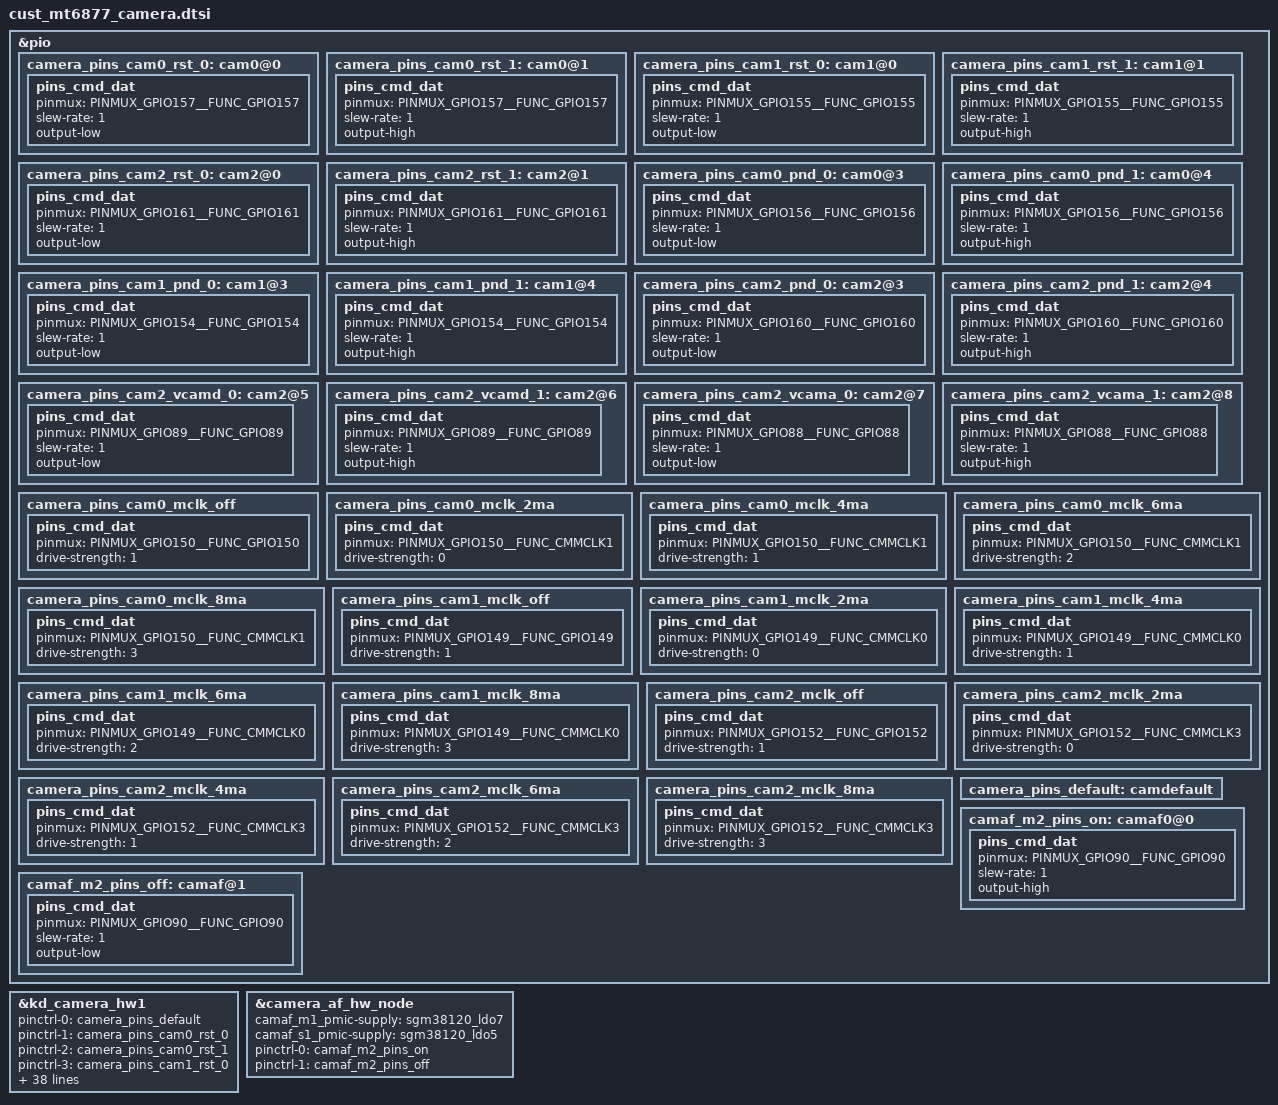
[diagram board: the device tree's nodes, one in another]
// SPDX-License-Identifier: GPL-2.0
/*
 * Copyright (c) 2021 MediaTek Inc.
 */

/* CAMERA GPIO standardization */
&pio {
	camera_pins_cam0_rst_0: cam0@0 {
		pins_cmd_dat {
			pinmux = <PINMUX_GPIO157__FUNC_GPIO157>;
			slew-rate = <1>;
			output-low;
		};
	};
	camera_pins_cam0_rst_1: cam0@1 {
		pins_cmd_dat {
			pinmux = <PINMUX_GPIO157__FUNC_GPIO157>;
			slew-rate = <1>;
			output-high;
		};
	};

	camera_pins_cam1_rst_0: cam1@0 {
		pins_cmd_dat {
			pinmux = <PINMUX_GPIO155__FUNC_GPIO155>;
			slew-rate = <1>;
			output-low;
		};
	};
	camera_pins_cam1_rst_1: cam1@1 {
		pins_cmd_dat {
			pinmux = <PINMUX_GPIO155__FUNC_GPIO155>;
			slew-rate = <1>;
			output-high;
		};
	};

	camera_pins_cam2_rst_0: cam2@0 {
		pins_cmd_dat {
			pinmux = <PINMUX_GPIO161__FUNC_GPIO161>;
			slew-rate = <1>;
			output-low;
		};
	};
	camera_pins_cam2_rst_1: cam2@1 {
		pins_cmd_dat {
			pinmux = <PINMUX_GPIO161__FUNC_GPIO161>;
			slew-rate = <1>;
			output-high;
		};
	};
	
	camera_pins_cam0_pnd_0: cam0@3 {
		pins_cmd_dat {
			pinmux = <PINMUX_GPIO156__FUNC_GPIO156>;
			slew-rate = <1>;
			output-low;
		};
	};
	camera_pins_cam0_pnd_1: cam0@4 {
		pins_cmd_dat {
			pinmux = <PINMUX_GPIO156__FUNC_GPIO156>;
			slew-rate = <1>;
			output-high;
		};
	};

	camera_pins_cam1_pnd_0: cam1@3 {
		pins_cmd_dat {
			pinmux = <PINMUX_GPIO154__FUNC_GPIO154>;
			slew-rate = <1>;
			output-low;
		};
	};
	camera_pins_cam1_pnd_1: cam1@4 {
		pins_cmd_dat {
			pinmux = <PINMUX_GPIO154__FUNC_GPIO154>;
			slew-rate = <1>;
			output-high;
		};
	};

	camera_pins_cam2_pnd_0: cam2@3 {
		pins_cmd_dat {
			pinmux = <PINMUX_GPIO160__FUNC_GPIO160>;
			slew-rate = <1>;
			output-low;
		};
	};
	camera_pins_cam2_pnd_1: cam2@4 {
		pins_cmd_dat {
			pinmux = <PINMUX_GPIO160__FUNC_GPIO160>;
			slew-rate = <1>;
			output-high;
		};
	};

	camera_pins_cam2_vcamd_0: cam2@5 {
		pins_cmd_dat {
			pinmux = <PINMUX_GPIO89__FUNC_GPIO89>;
			slew-rate = <1>;
			output-low;
		};
	};
	
	camera_pins_cam2_vcamd_1: cam2@6 {
		pins_cmd_dat {
			pinmux = <PINMUX_GPIO89__FUNC_GPIO89>;
			slew-rate = <1>;
			output-high;
		};
	};
	
	camera_pins_cam2_vcama_0: cam2@7 {
		pins_cmd_dat {
			pinmux = <PINMUX_GPIO88__FUNC_GPIO88>;
			slew-rate = <1>;
			output-low;
		};
	};
	
	camera_pins_cam2_vcama_1: cam2@8 {
		pins_cmd_dat {
			pinmux = <PINMUX_GPIO88__FUNC_GPIO88>;
			slew-rate = <1>;
			output-high;
		};
	};

	camera_pins_cam0_mclk_off: camera_pins_cam0_mclk_off {
		pins_cmd_dat {
			pinmux = <PINMUX_GPIO150__FUNC_GPIO150>;
			drive-strength = <1>;
		};
	};
	camera_pins_cam0_mclk_2ma: camera_pins_cam0_mclk_2ma {
		pins_cmd_dat {
			pinmux = <PINMUX_GPIO150__FUNC_CMMCLK1>;
			drive-strength = <0>;
		};
	};
	camera_pins_cam0_mclk_4ma: camera_pins_cam0_mclk_4ma {
		pins_cmd_dat {
			pinmux = <PINMUX_GPIO150__FUNC_CMMCLK1>;
			drive-strength = <1>;
		};
	};
	camera_pins_cam0_mclk_6ma: camera_pins_cam0_mclk_6ma {
		pins_cmd_dat {
			pinmux = <PINMUX_GPIO150__FUNC_CMMCLK1>;
			drive-strength = <2>;
		};
	};
	camera_pins_cam0_mclk_8ma: camera_pins_cam0_mclk_8ma {
		pins_cmd_dat {
			pinmux = <PINMUX_GPIO150__FUNC_CMMCLK1>;
			drive-strength = <3>;
		};
	};
	camera_pins_cam1_mclk_off: camera_pins_cam1_mclk_off {
		pins_cmd_dat {
			pinmux = <PINMUX_GPIO149__FUNC_GPIO149>;
			drive-strength = <1>;
		};
	};
	camera_pins_cam1_mclk_2ma: camera_pins_cam1_mclk_2ma {
		pins_cmd_dat {
			pinmux = <PINMUX_GPIO149__FUNC_CMMCLK0>;
			drive-strength = <0>;
		};
	};
	camera_pins_cam1_mclk_4ma: camera_pins_cam1_mclk_4ma {
		pins_cmd_dat {
			pinmux = <PINMUX_GPIO149__FUNC_CMMCLK0>;
			drive-strength = <1>;
		};
	};
	camera_pins_cam1_mclk_6ma: camera_pins_cam1_mclk_6ma {
		pins_cmd_dat {
			pinmux = <PINMUX_GPIO149__FUNC_CMMCLK0>;
			drive-strength = <2>;
		};
	};
	camera_pins_cam1_mclk_8ma: camera_pins_cam1_mclk_8ma {
		pins_cmd_dat {
			pinmux = <PINMUX_GPIO149__FUNC_CMMCLK0>;
			drive-strength = <3>;
		};
	};
	camera_pins_cam2_mclk_off: camera_pins_cam2_mclk_off {
		pins_cmd_dat {
			pinmux = <PINMUX_GPIO152__FUNC_GPIO152>;
			drive-strength = <1>;
		};
	};
	camera_pins_cam2_mclk_2ma: camera_pins_cam2_mclk_2ma {
		pins_cmd_dat {
			pinmux = <PINMUX_GPIO152__FUNC_CMMCLK3>;
			drive-strength = <0>;
		};
	};
	camera_pins_cam2_mclk_4ma: camera_pins_cam2_mclk_4ma {
		pins_cmd_dat {
			pinmux = <PINMUX_GPIO152__FUNC_CMMCLK3>;
			drive-strength = <1>;
		};
	};
	camera_pins_cam2_mclk_6ma: camera_pins_cam2_mclk_6ma {
		pins_cmd_dat {
			pinmux = <PINMUX_GPIO152__FUNC_CMMCLK3>;
			drive-strength = <2>;
		};
	};
	camera_pins_cam2_mclk_8ma: camera_pins_cam2_mclk_8ma {
		pins_cmd_dat {
			pinmux = <PINMUX_GPIO152__FUNC_CMMCLK3>;
			drive-strength = <3>;
		};
	};
	camera_pins_default: camdefault {
	};
};

&kd_camera_hw1 {
	pinctrl-names = "default",
			"cam0_rst0", "cam0_rst1",
			"cam1_rst0", "cam1_rst1",
			"cam2_rst0", "cam2_rst1",
			"cam2_ldo_vcamd_0", "cam2_ldo_vcamd_1",
			"cam2_ldo_vcama_0", "cam2_ldo_vcama_1",
			"cam0_mclk_off",
			"cam0_mclk_2mA", "cam0_mclk_4mA",
			"cam0_mclk_6mA", "cam0_mclk_8mA",
			"cam1_mclk_off",
			"cam1_mclk_2mA", "cam1_mclk_4mA",
			"cam1_mclk_6mA", "cam1_mclk_8mA",
			"cam2_mclk_off",
			"cam2_mclk_2mA", "cam2_mclk_4mA",
			"cam2_mclk_6mA", "cam2_mclk_8mA",
			"cam0_pnd0", "cam0_pnd1",
			"cam1_pnd0", "cam1_pnd1",
			"cam2_pnd0", "cam2_pnd1";

	pinctrl-0 = <&camera_pins_default>;
	pinctrl-1 = <&camera_pins_cam0_rst_0>;
	pinctrl-2 = <&camera_pins_cam0_rst_1>;
	pinctrl-3 = <&camera_pins_cam1_rst_0>;
	pinctrl-4 = <&camera_pins_cam1_rst_1>;
	pinctrl-5 = <&camera_pins_cam2_rst_0>;
	pinctrl-6 = <&camera_pins_cam2_rst_1>;
	pinctrl-7 = <&camera_pins_cam2_vcamd_0>;
	pinctrl-8 = <&camera_pins_cam2_vcamd_1>;
	pinctrl-9 = <&camera_pins_cam2_vcama_0>;
	pinctrl-10 = <&camera_pins_cam2_vcama_1>;
	pinctrl-11 = <&camera_pins_cam0_mclk_off>;
	pinctrl-12 = <&camera_pins_cam0_mclk_2ma>;
	pinctrl-13 = <&camera_pins_cam0_mclk_4ma>;
	pinctrl-14 = <&camera_pins_cam0_mclk_6ma>;
	pinctrl-15 = <&camera_pins_cam0_mclk_8ma>;
	pinctrl-16 = <&camera_pins_cam1_mclk_off>;
	pinctrl-17 = <&camera_pins_cam1_mclk_2ma>;
	pinctrl-18 = <&camera_pins_cam1_mclk_4ma>;
	pinctrl-19 = <&camera_pins_cam1_mclk_6ma>;
	pinctrl-20 = <&camera_pins_cam1_mclk_8ma>;
	pinctrl-21 = <&camera_pins_cam2_mclk_off>;
	pinctrl-22 = <&camera_pins_cam2_mclk_2ma>;
	pinctrl-23 = <&camera_pins_cam2_mclk_4ma>;
	pinctrl-24 = <&camera_pins_cam2_mclk_6ma>;
	pinctrl-25 = <&camera_pins_cam2_mclk_8ma>;
	pinctrl-26 = <&camera_pins_cam0_pnd_0>;
	pinctrl-27 = <&camera_pins_cam0_pnd_1>;
	pinctrl-28 = <&camera_pins_cam1_pnd_0>;
	pinctrl-29 = <&camera_pins_cam1_pnd_1>;
	pinctrl-30 = <&camera_pins_cam2_pnd_0>;
	pinctrl-31 = <&camera_pins_cam2_pnd_1>;
	
	/* main (wide) : ldo4 ldo8 --- AVDD_CAM_W, DVDD_CAM_W */
	cam0_vcama-supply = <&sgm38120_ldo3>;
	cam0_vcamd-supply = <&sgm38120_ldo1>;
	cam0_vcamio-supply = <&sgm38120_ldo6>;
//	cam0_vcamaf-supply = <&sgm38120_ldo7>;

	/* front */
	cam1_vcama-supply = <&sgm38120_ldo4>;
	cam1_vcamd-supply = <&sgm38120_ldo2>;
	cam1_vcamio-supply = <&sgm38120_ldo6>;
//	cam1_vcamaf-supply = <&sgm38120_ldo5>;
	
	/* main2 (tele) */
	cam2_vcamio-supply = <&sgm38120_ldo6>;

	cam0_enable_sensor = "imx350_mipi_raw" ;
	cam1_enable_sensor = "imx135_mipi_raw";
	cam2_enable_sensor = "gc2375h_mipi_raw";
//	cam2_enable_sensor = "bf2257_mipi_raw";
	
	status = "okay";
};
/* CAMERA GPIO end */

/* CAMERA EEPROM */
#if  0
&i2c2 {
	mtk_camera_eeprom4:camera_eeprom4@51 {
		compatible = "mediatek,camera_eeprom";
		reg = <0x51>;
		status = "okay";
	};
};

&i2c4 {
	mtk_camera_eeprom1:camera_eeprom1@51 {
		compatible = "mediatek,camera_eeprom";
		reg = <0x51>;
		status = "okay";
	};
	mtk_camera_eeprom2:camera_eeprom2@50 {
		compatible = "mediatek,camera_eeprom";
		reg = <0x50>;
		status = "okay";
	};
};
&i2c8 {
	mtk_camera_eeprom0:camera_eeprom0@50 {
		compatible = "mediatek,camera_eeprom";
		reg = <0x50>;
		status = "okay";
	};
};
#endif /* #if 0 */

/* CAMERA EEPROM end */

/* CAMERA AF */
&camera_af_hw_node {
	pinctrl-names = "camaf_m2_gpio_on", "camaf_m2_gpio_off";
	camaf_m1_pmic-supply = <&sgm38120_ldo7>;
	camaf_s1_pmic-supply = <&sgm38120_ldo5>;
	pinctrl-0 = <&camaf_m2_pins_on>;
	pinctrl-1 = <&camaf_m2_pins_off>;
	status = "okay";
};

&pio {
	camaf_m2_pins_on: camaf0@0 {
		pins_cmd_dat {
			pinmux = <PINMUX_GPIO90__FUNC_GPIO90>;
			slew-rate = <1>;
			output-high;
		};
	};
	camaf_m2_pins_off: camaf@1 {
		pins_cmd_dat {
			pinmux = <PINMUX_GPIO90__FUNC_GPIO90>;
			slew-rate = <1>;
			output-low;
		};
	};
};
/* CAMERA AF end */
